# V32F20x_CM0 register map
File version: 1.0.1
CPU: CM0 r0p0, little endian, no MPU, no FPU, 2 interrupt priority bits
Registers are 32-bit, read-write, reset 0x0 unless marked. A register's access mark holds for its fields unless they carry their own. Offsets are from the block's base; [hi:lo] are bit positions.

## BSPI0 — BSPI0 Peripheral Interface
Base 0x41020000
Same registers: BSPI1 0x41020800, BSPI2 0x41021000, BSPI3 0x41021800, BSPI4 0x41022000, BSPI5 0x41022800
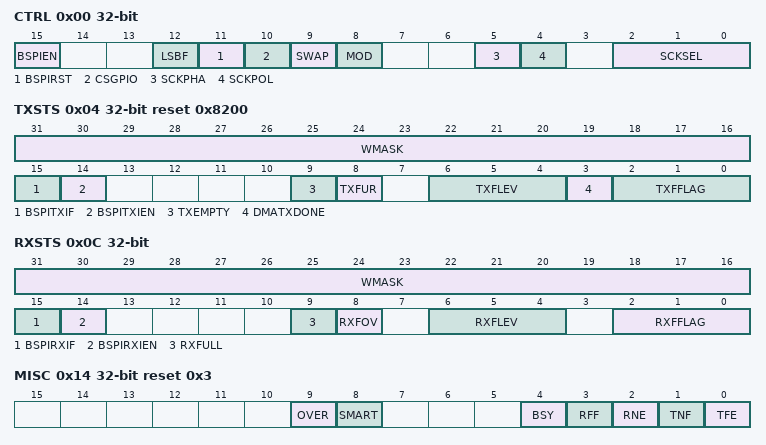
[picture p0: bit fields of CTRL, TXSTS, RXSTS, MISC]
0x00 CTRL — BSPI control Register
  [15] BSPIEN — BSPI enable.
  [12] LSBF — BSPI LSB control.
  [11] BSPIRST — BSPI software reset.
  [10] CSGPIO — The control owner of BSPICS.
  [9] SWAP — BSPI MISO/MOSI swap control.
  [8] MOD — BSPI Mode Selection register.
  [5] SCKPHA — BSPI clock phase.
  [4] SCKPOL — BSPI clock polarity.
  [2:0] SCKSEL — Master mode clock selection.
0x04 TXSTS reset 0x8200 — BSPI transmit status register
  [31:16] WMASK — Write mask bit
  [15] BSPITXIF — BSPI Transmit Interrupt flag.
  [14] BSPITXIEN — BSPI Transmit Interrupt Enable.
  [9] TXEMPTY — Transmot FIFO empty register.
  [8] TXFUR — Transmit FIFO under run register.
  [6:4] TXFLEV — Transmit FIFO interrupt level register.
  [3] DMATXDONE — Transfer done flag will auto set 1 after transmit all the data
  [2:0] TXFFLAG — Transmit FIFO Data Level.
0x08 TXDAT wo — BSPI transmit FIFO register
  [7:0] BSPITXDATA — Write data to BSPI Transmit FIFO.
0x0C RXSTS — BSPI receive status register
  [31:16] WMASK — Write mask bit
  [15] BSPIRXIF — BSPI Transmit Interrupt flag.
  [14] BSPIRXIEN — BSPI Receive Interrupt Enable.
  [9] RXFULL — Receive FIFO full register.
  [8] RXFOV — Receive FIFO over run register.
  [6:4] RXFLEV — Receive FIFO interrupt level register.
  [2:0] RXFFLAG — Receive FIFO Data Level.
0x10 RXDAT ro — BSPI receive FIFO register
  [7:0] BSPIRXDATA — Read data from BSPI Receive Buffer.
0x14 MISC reset 0x3 — BSPI Misc. control register
  [9] OVER — BSPI FIFO over write mode enable control.
  [8] SMART — BSPI FIFO smart mode control.
  [4] BSY — BSPI Controller busy flag.
  [3] RFF — Receive FIFO full flag.
  [2] RNE — Receive FIFO Not Empty Flag.
  [1] TNF — Transmit FIFO Not Full Flag.
  [0] TFE — Transmit FIFO empty flag.

## ISO78162 — ISO78162 Peripheral Interface
Base 0x41040000
Same registers: ISO78163 0x41040040
0x04 BAUDDIVL — ISO78160 baud-rate low byte register.
  [7:0] BAUDDIVL — Low byte of baud-rate divider.
0x08 BAUDDIVH — ISO78160 baud-rate high byte register.
  [7:0] BAUDDIVH — High byte of baud rate divider
0x0C DATA — ISO78160 data register.
  [7:0] DATA — Read Receive data when receive data is not read by programmer and another data has been received the OVIF flag will be set
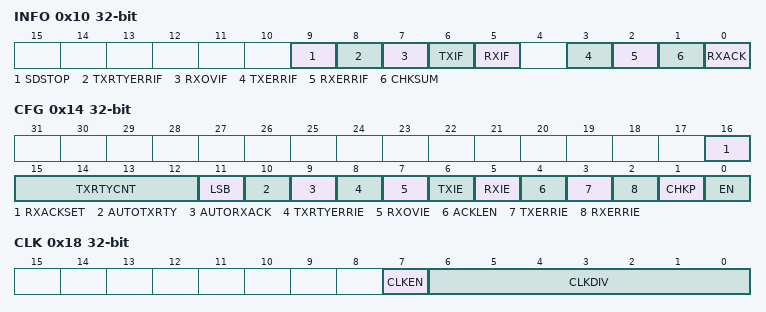
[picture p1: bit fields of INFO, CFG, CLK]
0x10 INFO ro — ISO78160 information register.
  [9] SDSTOP — Transmit finish flag.
  [8] TXRTYERRIF — Transmit Retry counter reach flag.
  [7] RXOVIF — Receive overflow flag.
  [6] TXIF — Transmit interrupt flag.
  [5] RXIF — Receive interrupt flag.
  [3] TXERRIF — When AUTOTXRTY is 0 this bit will be set to 1 when a transfer is completed and received ACK is 0
  [2] RXERRIF — When received data have check sum error this bit will be set to 1
  [1] CHKSUM — The received data s check sum bit
  [0] RXACK — The received ACK at the end of transmit
0x14 CFG — ISO78160 control register.
  [16] RXACKSET — RXACK length.
  [15:12] TXRTYCNT — Transmit retry number control register.
  [11] LSB — MSB/LSB transmit order control register.
  [10] AUTOTXRTY — Automatic transmit retry when receive ACK is 0.
  [9] AUTORXACK — Automatic response ACK as 0 when receive an error data to let transmitter re send the data
  [8] TXRTYERRIE — Transmit retry error interrupt enable register.
  [7] RXOVIE — Receive overrun interrupt enable register.
  [6] TXIE — Transmit interrupt enable register.
  [5] RXIE — Receive interrupt enable register.
  [4] ACKLEN — ACK low period when receive an error data.
  [3] TXERRIE — Transmitted data error interrupt enable register.
  [2] RXERRIE — Received data error interrupt enable register.
  [1] CHKP — Parity mode control register.
  [0] EN — ISO7816 enable register.
0x18 CLK — ISO78160 clock divider control register.
  [7] CLKEN — ISO7816 clock output enable.
  [6:0] CLKDIV — The ISO7816 clock divider ratio.
